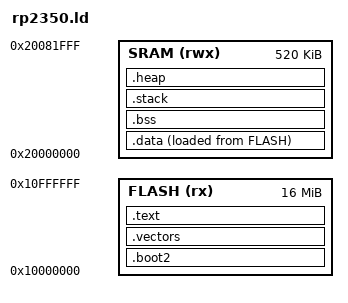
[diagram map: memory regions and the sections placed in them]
/**
 * @file rp2350.ld
 * @brief RP2350 链接脚本
 */

/*============================================================================
 * 内存布局
 *============================================================================*/

MEMORY
{
    /* Flash: 16MB 外部 Flash (XIP) */
    FLASH (rx)  : ORIGIN = 0x10000000, LENGTH = 16M

    /* SRAM: 520KB */
    SRAM (rwx)  : ORIGIN = 0x20000000, LENGTH = 520K
}

/*============================================================================
 * 入口点
 *============================================================================*/

ENTRY(_boot2_entry)

/*============================================================================
 * 段定义
 *============================================================================*/

SECTIONS
{
    /*--------------------------------------------
     * Stage2 Bootloader
     * 必须放在 Flash 起始位置
     *--------------------------------------------*/
    .boot2 : {
        *(.boot2)
        . = ALIGN(4);
    } > FLASH

    /*--------------------------------------------
     * 向量表
     *--------------------------------------------*/
    .vectors : {
        . = ALIGN(256);         /* 向量表必须 256 字节对齐 */
        _vectors = .;
        KEEP(*(.vectors))
        . = ALIGN(4);
    } > FLASH

    /*--------------------------------------------
     * 代码段
     *--------------------------------------------*/
    .text : {
        *(.text*)
        *(.text)
        . = ALIGN(4);

        /* 只读数据 */
        *(.rodata*)
        *(.rodata)
        . = ALIGN(4);
    } > FLASH

    /*--------------------------------------------
     * 数据段
     * LMA 在 Flash, VMA 在 SRAM
     *--------------------------------------------*/
    _sidata = LOADADDR(.data);

    .data : {
        . = ALIGN(4);
        _sdata = .;
        *(.data*)
        *(.data)
        . = ALIGN(4);
        _edata = .;
    } > SRAM AT > FLASH

    /*--------------------------------------------
     * BSS 段 (未初始化数据)
     *--------------------------------------------*/
    .bss : {
        . = ALIGN(4);
        _sbss = .;
        *(.bss*)
        *(.bss)
        *(COMMON)
        . = ALIGN(4);
        _ebss = .;
    } > SRAM

    /*--------------------------------------------
     * 栈
     *--------------------------------------------*/
    .stack (NOLOAD) : {
        . = ALIGN(8);
        _sstack = .;
        . = . + 0x2000;         /* 8KB 栈空间 */
        _estack = .;
    } > SRAM

    /*--------------------------------------------
     * 堆 (剩余 SRAM)
     *--------------------------------------------*/
    .heap (NOLOAD) : {
        . = ALIGN(8);
        _sheap = .;
        . = ORIGIN(SRAM) + LENGTH(SRAM) - 1;
        _eheap = .;
    } > SRAM

    /*--------------------------------------------
     * 丢弃的段
     *--------------------------------------------*/
    /DISCARD/ : {
        *(.comment)
        *(.note*)
        *(.ARM.attributes*)
    }
}

/*============================================================================
 * 符号导出
 *============================================================================*/

/* 栈顶 */
_estack = ORIGIN(SRAM) + LENGTH(SRAM);

/* 堆范围 */
_sheap = _ebss;
_eheap = _estack - 0x2000;  /* 保留 8KB 给栈 */
